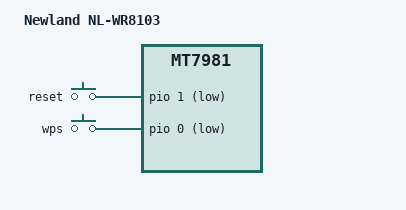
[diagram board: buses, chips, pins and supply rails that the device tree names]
// SPDX-License-Identifier: GPL-2.0-or-later OR MIT

/dts-v1/;
#include "mt7981b-newland_nl-wr8103-base.dtsi"

/ {
	model = "Newland NL-WR8103";
	compatible = "newland,nl-wr8103", "mediatek,mt7981";

	gpio-keys {
		compatible = "gpio-keys";

		reset {
			label = "reset";
			linux,code = <KEY_RESTART>;
			gpios = <&pio 1 GPIO_ACTIVE_LOW>;
		};

		wps {
			label = "wps";
			linux,code = <KEY_WPS_BUTTON>;
			gpios = <&pio 0 GPIO_ACTIVE_LOW>;
		};
	};
};
